# STM32H7R register map
File version: 1.4
CPU: CM7 r0p1, little endian, MPU, FPU, 4 interrupt priority bits
Registers are 32-bit, read-write, reset 0x0 unless marked. A register's access mark holds for its fields unless they carry their own. Offsets are from the block's base; [hi:lo] are bit positions; {n}, {i} and the like mark numbered series; 'fields as' and 'values as' point back to an identical list; <NAME> marks a mode.

## ETH (part 3 of 4) — Ethernet register block
Base 0x40028000
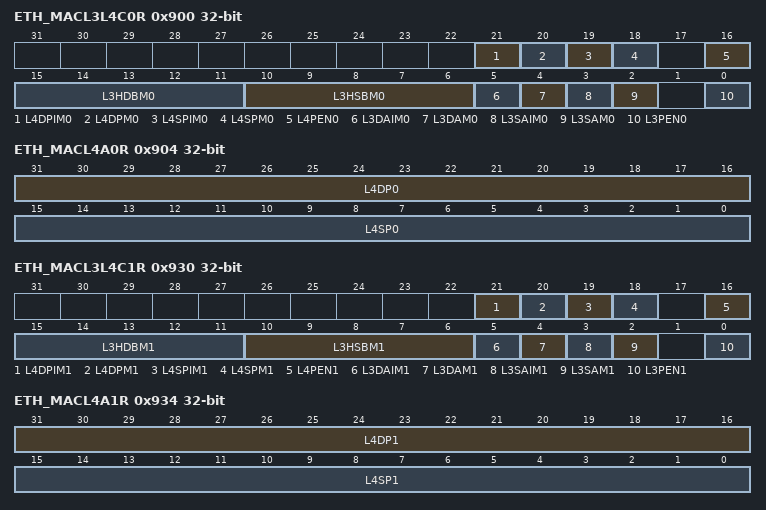
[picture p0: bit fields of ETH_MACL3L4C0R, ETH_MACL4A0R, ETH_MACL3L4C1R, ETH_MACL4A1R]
0x900 ETH_MACL3L4C0R — L3 and L4 control 0 register
  [21] L4DPIM0 — Layer 4 Destination Port Inverse Match Enable When this bit is set, the Layer 4 Destination Port number field is enabled for inverse matching. When this bit is reset, the Layer 4 Destination Port number field is enabled for perfect matching. This bit is valid and applicable only when the L4DPM0 bit is set high.
  [20] L4DPM0 — Layer 4 Destination Port Match Enable When this bit is set, the Layer 4 Destination Port number field is enabled for matching. When this bit is reset, the MAC ignores the Layer 4 Destination Port number field for matching.
  [19] L4SPIM0 — Layer 4 Source Port Inverse Match Enable When this bit is set, the Layer 4 Source Port number field is enabled for inverse matching. When this bit is reset, the Layer 4 Source Port number field is enabled for perfect matching. This bit is valid and applicable only when the L4SPM0 bit is set high.
  [18] L4SPM0 — Layer 4 Source Port Match Enable When this bit is set, the Layer 4 Source Port number field is enabled for matching. When this bit is reset, the MAC ignores the Layer 4 Source Port number field for matching.
  [16] L4PEN0 — Layer 4 Protocol Enable When this bit is set, the Source and Destination Port number fields of UDP packets are used for matching. When this bit is reset, the Source and Destination Port number fields of TCP packets are used for matching. The Layer 4 matching is done only when the L4SPM0 or L4DPM0 bit is set.
  [15:11] L3HDBM0 — Layer 3 IP DA higher bits match This field contains the number of higher bits of IP Destination Address that are masked in the IPv4 packets: .. Bits[12:11] of this field correspond to Bits[6:5] of L3HSBM0 which indicate the number of lower bits of IP Source or Destination Address that are masked in the IPv6 packets. Number of bits masked is given by concatenated values of the L3HDBM0[1:0] and L3HSBM0 bits: .. This field is valid and applicable only when the L3DAM0 or L3SAM0 bit is set.
    0=B_0x0_IPV4_PACKETS (No bits are masked.); 1=B_0x1_IPV4_PACKETS (LSb[0] is masked)
  [10:6] L3HSBM0 — Layer 3 IP SA higher bits match This field contains the number of lower bits of IP source address that are masked for matching in the IPv4 packets. The following list describes the values of this field: .. Condition: IPv6 packets: This field contains Bits[4:0] of L3HSBM0. These bits indicate the number of higher bits of IP source or destination address matched in the IPv6 packets. This field is valid and applicable only when the L3DAM0 or L3SAM0 bit is set high.
    values as L3HDBM0
  [5] L3DAIM0 — Layer 3 IP DA Inverse Match Enable When this bit is set, the Layer 3 IP Destination Address field is enabled for inverse matching. When this bit is reset, the Layer 3 IP Destination Address field is enabled for perfect matching. This bit is valid and applicable only when the L3DAM0 bit is set high.
  [4] L3DAM0 — Layer 3 IP DA Match Enable When this bit is set, the Layer 3 IP Destination Address field is enabled for matching. When this bit is reset, the MAC ignores the Layer 3 IP Destination Address field for matching. Note: When the L3PEN0 bit is set, you should set either this bit or the L3SAM0 bit because either IPv6 DA or SA can be checked for filtering.
  [3] L3SAIM0 — Layer 3 IP SA Inverse Match Enable When this bit is set, the Layer 3 IP Source Address field is enabled for inverse matching. When this bit reset, the Layer 3 IP Source Address field is enabled for perfect matching. This bit is valid and applicable only when the L3SAM0 bit is set.
  [2] L3SAM0 — Layer 3 IP SA Match Enable When this bit is set, the Layer 3 IP Source Address field is enabled for matching. When this bit is reset, the MAC ignores the Layer 3 IP Source Address field for matching. Note: When the L3PEN0 bit is set, you should set either this bit or the L3DAM0 bit because either IPv6 SA or DA can be checked for filtering.
  [0] L3PEN0 — Layer 3 Protocol Enable When this bit is set, the Layer 3 IP Source or Destination Address matching is enabled for IPv6 packets. When this bit is reset, the Layer 3 IP Source or Destination Address matching is enabled for IPv4 packets. The Layer 3 matching is done only when the L3SAM0 or L3DAM0 bit is set.
0x904 ETH_MACL4A0R — Layer4 Address filter 0 register
  [31:16] L4DP0 — Layer 4 Destination Port Number Field When the L4PEN0 bit is reset and the L4DPM0 bit is set in the L3 and L4 control 0 register (ETH_MACL3L4C0R), this field contains the value to be matched with the TCP Destination Port Number field in the IPv4 or IPv6 packets. When the L4PEN0 and L4DPM0 bits are set in L3 and L4 control 0 register (ETH_MACL3L4C0R), this field contains the value to be matched with the UDP Destination Port Number field in the IPv4 or IPv6 packets.
  [15:0] L4SP0 — Layer 4 Source Port Number Field When the L4PEN0 bit is reset and the L4DPM0 bit is set in the L3 and L4 control 0 register (ETH_MACL3L4C0R), this field contains the value to be matched with the TCP Source Port Number field in the IPv4 or IPv6 packets. When the L4PEN0 and L4DPM0 bits are set in L3 and L4 control 0 register (ETH_MACL3L4C0R), this field contains the value to be matched with the UDP Source Port Number field in the IPv4 or IPv6 packets.
0x910 ETH_MACL3A00R — Layer3 Address 0 filter 0 register
  [31:0] L3A00 — Layer 3 Address 0 Field When the L3PEN0 and L3SAM0 bits are set in the L3 and L4 control 0 register (ETH_MACL3L4C0R), this field contains the value to be matched with Bits[31:0] of the IP Source Address field in the IPv6 packets. When the L3PEN0 and L3DAM0 bits are set in the L3 and L4 control 0 register (ETH_MACL3L4C0R), this field contains the value to be matched with Bits[31:0] of the IP Destination Address field in the IPv6 packets. When the L3PEN0 bit is reset and the L3SAM0 bit is set in the L3 and L4 control 0 register (ETH_MACL3L4C0R), this field contains the value to be matched with the IP Source Address field in the IPv4 packets.
0x914 ETH_MACL3A10R — Layer3 Address 1 filter 0 register
  [31:0] L3A10 — Layer 3 Address 1 Field When the L3PEN0 and L3SAM0 bits are set in the L3 and L4 control 0 register (ETH_MACL3L4C0R), this field contains the value to be matched with Bits[63:32] of the IP Source Address field in the IPv6 packets. When the L3PEN0 and L3DAM0 bits are set in the L3 and L4 control 0 register (ETH_MACL3L4C0R), this field contains the value to be matched with Bits[63:32] of the IP Destination Address field in the IPv6 packets. When the L3PEN0 bit is reset and the L3SAM0 bit is set in the L3 and L4 control 0 register (ETH_MACL3L4C0R), this field contains the value to be matched with the IP Destination Address field in the IPv4 packets.
0x918 ETH_MACL3A20R — Layer3 Address 2 filter 0 register
  [31:0] L3A20 — Layer 3 Address 2 Field When the L3PEN0 and L3SAM0 bits are set in the L3 and L4 control 0 register (ETH_MACL3L4C0R), this field contains the value to be matched with Bits[95:64] of the IP Source Address field in the IPv6 packets. When the L3PEN0 and L3DAM0 bits are set in the L3 and L4 control 0 register (ETH_MACL3L4C0R), this field contains the value to be matched with Bits[95:64] of the IP Destination Address field in the IPv6 packets. When the L3PEN0 bit is reset in the L3 and L4 control 0 register (ETH_MACL3L4C0R), this field is not used.
0x91C ETH_MACL3A30R — Layer3 Address 3 filter 0 register
  [31:0] L3A30 — Layer 3 Address 3 Field When the L3PEN0 and L3SAM0 bits are set in the L3 and L4 control 0 register (ETH_MACL3L4C0R), this field contains the value to be matched with Bits[127:96] of the IP Source Address field in the IPv6 packets. When the L3PEN0 and L3DAM0 bits are set in the L3 and L4 control 0 register (ETH_MACL3L4C0R), this field contains the value to be matched with Bits[127:96] of the IP Destination Address field in the IPv6 packets. When the L3PEN0 bit is reset in the L3 and L4 control 0 register (ETH_MACL3L4C0R), this field is not used.
0x930 ETH_MACL3L4C1R — L3 and L4 control 1 register
  [21] L4DPIM1 — Layer 4 Destination Port Inverse Match Enable When this bit is set, the Layer 4 Destination Port number field is enabled for inverse matching. When this bit is reset, the Layer 4 Destination Port number field is enabled for perfect matching. This bit is valid and applicable only when the L4DPM1 bit is set high.
  [20] L4DPM1 — Layer 4 Destination Port Match Enable When this bit is set, the Layer 4 Destination Port number field is enabled for matching. When this bit is reset, the MAC ignores the Layer 4 Destination Port number field for matching.
  [19] L4SPIM1 — Layer 4 Source Port Inverse Match Enable When this bit is set, the Layer 4 Source Port number field is enabled for inverse matching. When this bit is reset, the Layer 4 Source Port number field is enabled for perfect matching. This bit is valid and applicable only when the L4SPM1 bit is set high.
  [18] L4SPM1 — Layer 4 Source Port Match Enable When this bit is set, the Layer 4 Source Port number field is enabled for matching. When this bit is reset, the MAC ignores the Layer 4 Source Port number field for matching.
  [16] L4PEN1 — Layer 4 Protocol Enable When this bit is set, the Source and Destination Port number fields of UDP packets are used for matching. When this bit is reset, the Source and Destination Port number fields of TCP packets are used for matching. The Layer 4 matching is done only when the L4SPM1 or L4DPM1 bit is set.
  [15:11] L3HDBM1 — Layer 3 IP DA higher bits match This field contains the number of lower bits of IP Destination Address that are masked for matching in the IPv4 packets. The following list describes the values of this field: .. Bits[12:11] of this field correspond to Bits[6:5] of L3HSBM1, which indicate the number of lower bits of IP Source or Destination Address that are masked in the IPv6 packets. The following list describes the concatenated values of the L3HDBM1[1:0] and L3HSBM1 bits: .. This field is valid and applicable only when the L3DAM1 or L3SAM1 bit is set.
    values as ETH_MACL3L4C0R.L3HDBM0
  [10:6] L3HSBM1 — Layer 3 IP SA Higher Bits Match This field contains the number of lower bits of IP Source Address that are masked for matching in the IPv4 packets. The following list describes the values of this field: .. This field contains Bits[4:0] of L3HSBM1. These bits indicate the number of higher bits of IP Source or Destination Address matched in the IPv6 packets. This field is valid and applicable only when the L3DAM1 or L3SAM1 bit is set high.
    values as ETH_MACL3L4C0R.L3HDBM0
  [5] L3DAIM1 — Layer 3 IP DA Inverse Match Enable When this bit is set, the Layer 3 IP Destination Address field is enabled for inverse matching. When this bit is reset, the Layer 3 IP Destination Address field is enabled for perfect matching. This bit is valid and applicable only when the L3DAM1 bit is set high.
  [4] L3DAM1 — Layer 3 IP DA Match Enable When this bit is set, the Layer 3 IP Destination Address field is enabled for matching. When this bit is reset, the MAC ignores the Layer 3 IP Destination Address field for matching. Note: When the L3PEN1 bit is set, you should set either this bit or the L3SAM1 bit because either IPv6 DA or SA can be checked for filtering.
  [3] L3SAIM1 — Layer 3 IP SA Inverse Match Enable When this bit is set, the Layer 3 IP Source Address field is enabled for inverse matching. When this bit reset, the Layer 3 IP Source Address field is enabled for perfect matching. This bit is valid and applicable only when the L3SAM1 bit is set.
  [2] L3SAM1 — Layer 3 IP SA Match Enable When this bit is set, the Layer 3 IP Source Address field is enabled for matching. When this bit is reset, the MAC ignores the Layer 3 IP Source Address field for matching. Note: When the L3PEN01 bit is set, you should set either this bit or the L3DAM1 bit because either IPv6 SA or DA can be checked for filtering.
  [0] L3PEN1 — Layer 3 Protocol Enable When this bit is set, the Layer 3 IP Source or Destination Address matching is enabled for IPv6 packets. When this bit is reset, the Layer 3 IP Source or Destination Address matching is enabled for IPv4 packets. The Layer 3 matching is done only when the L3SAM1 or L3DAM1 bit is set.
0x934 ETH_MACL4A1R — Layer 4 address filter 1 register
  [31:16] L4DP1 — Layer 4 Destination Port Number Field When the L4PEN1 bit is reset and the L4DPM1 bit is set in the L3 and L4 control 1 register (ETH_MACL3L4C1R), this field contains the value to be matched with the TCP Destination Port Number field in the IPv4 or IPv6 packets. When the L4PEN1 and L4DPM1 bits are set in L3 and L4 control 1 register (ETH_MACL3L4C1R), this field contains the value to be matched with the UDP Destination Port Number field in the IPv4 or IPv6 packets.
  [15:0] L4SP1 — Layer 4 Source Port Number Field When the L4PEN1 bit is reset and the L4DPM1 bit is set in the L3 and L4 control 1 register (ETH_MACL3L4C1R), this field contains the value to be matched with the TCP Source Port Number field in the IPv4 or IPv6 packets. When the L4PEN1 and L4DPM1 bits are set in L3 and L4 control 1 register (ETH_MACL3L4C1R), this field contains the value to be matched with the UDP Source Port Number field in the IPv4 or IPv6 packets.
0x940 ETH_MACL3A01R — Layer3 address 0 filter 1 Register
  [31:0] L3A01 — Layer 3 Address 0 Field When the L3PEN1 and L3SAM1bits are set in the L3 and L4 control 1 register (ETH_MACL3L4C1R), this field contains the value to be matched with Bits[31:0] of the IP Source Address field in the IPv6 packets. When the L3PEN1 and L3DAM1 bits are set in the L3 and L4 control 1 register (ETH_MACL3L4C1R), this field contains the value to be matched with Bits[31:0] of the IP Destination Address field in the IPv6 packets. When the L3PEN1 bit is reset and the L3SAM1 bit is set in the L3 and L4 control 1 register (ETH_MACL3L4C1R), this field contains the value to be matched with the IP Source Address field in the IPv4 packets.
0x944 ETH_MACL3A11R — Layer3 address 1 filter 1 register
  [31:0] L3A11 — Layer 3 Address 1 Field When the L3PEN1 and L3SAM1 bits are set in the L3 and L4 control 1 register (ETH_MACL3L4C1R), this field contains the value to be matched with Bits[63:32] of the IP Source Address field in the IPv6 packets. When the L3PEN1 and L3DAM1 bits are set in the L3 and L4 control 1 register (ETH_MACL3L4C1R), this field contains the value to be matched with Bits[63:32] of the IP Destination Address field in the IPv6 packets. When the L3PEN1 bit is reset and the L3SAM1 bit is set in the L3 and L4 control 1 register (ETH_MACL3L4C1R), this field contains the value to be matched with the IP Destination Address field in the IPv4 packets.
0x948 ETH_MACL3A21R — Layer3 address 2 filter 1 Register
  [31:0] L3A21 — Layer 3 Address 2 Field When the L3PEN1 and L3SAM1 bits are set in the L3 and L4 control 1 register (ETH_MACL3L4C1R), this field contains the value to be matched with Bits[95:64] of the IP Source Address field in the IPv6 packets. When the L3PEN1 and L3DAM1 bits are set in the L3 and L4 control 1 register (ETH_MACL3L4C1R), this field contains the value to be matched with Bits[95:64] of the IP Destination Address field in the IPv6 packets. When the L3PEN1 bit is reset in the L3 and L4 control 1 register (ETH_MACL3L4C1R), this field is not used.
0x94C ETH_MACL3A31R — Layer3 address 3 filter 1 register
  [31:0] L3A31 — Layer 3 Address 3 Field When the L3PEN1 and L3SAM1 bits are set in the L3 and L4 control 1 register (ETH_MACL3L4C1R), this field contains the value to be matched with Bits[127:96] of the IP Source Address field in the IPv6 packets. When the L3PEN1 and L3DAM1 bits are set in the L3 and L4 control 1 register (ETH_MACL3L4C1R), this field contains the value to be matched with Bits[127:96] of the IP Destination Address field in the IPv6 packets. When the L3PEN1 bit is reset in the L3 and L4 control 1 register (ETH_MACL3L4C1R), this field is not used.
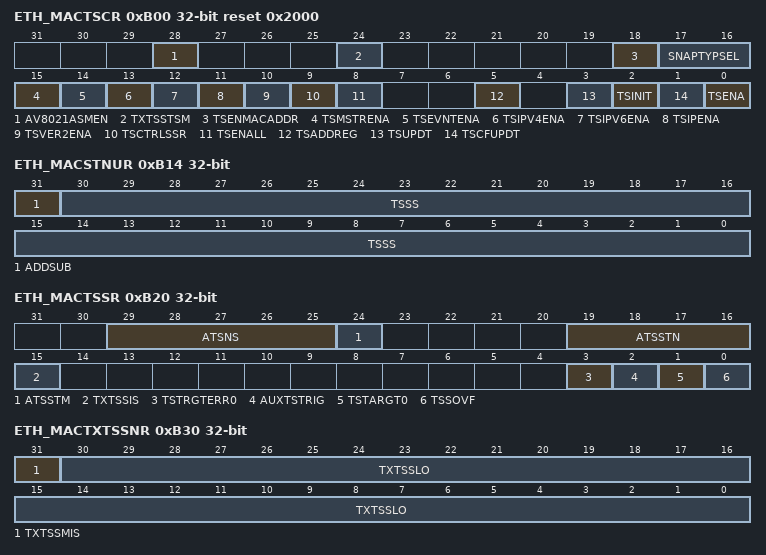
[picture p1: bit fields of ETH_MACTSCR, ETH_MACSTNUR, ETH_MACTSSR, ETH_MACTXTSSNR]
0xB00 ETH_MACTSCR reset 0x2000 — Timestamp control Register
  [28] AV8021ASMEN — AV 802.1AS Mode Enable When this bit is set, the MAC processes only untagged PTP over Ethernet packets for providing PTP status and capturing timestamp snapshots, that is, IEEE 802.1AS operating mode. When PTP offload feature is enabled, for the purpose of PTP offload, the transport specific field in the PTP header is generated and checked based on the value of this bit.
  [24] TXTSSTSM — Transmit Timestamp Status Mode When this bit is set, the MAC overwrites the earlier transmit timestamp status even if it is not read by the software. The MAC indicates this by setting the TXTSSMIS bit of the Tx timestamp status nanoseconds register (ETH_MACTXTSSNR) register. When this bit is reset, the MAC ignores the timestamp status of current packet if the timestamp status of previous packet is not read by the software. The MAC indicates this by setting the TXTSSMIS bit of the Tx timestamp status nanoseconds register (ETH_MACTXTSSNR).
  [18] TSENMACADDR — Enable MAC Address for PTP Packet Filtering When this bit is set, the DA MAC address (that matches any MAC Address register) is used to filter the PTP packets when PTP is directly sent over Ethernet. When this bit is set, received PTP packets with DA containing a special multicast or unicast address that matches the one programmed in MAC address registers are considered for processing as indicated below, when PTP is directly sent over Ethernet. For normal timestamping operation, MAC address registers 0 to 31 is considered for unicast destination address matching. For PTP offload, only MAC address register 0 is considered for unicast destination address matching.
  [17:16] SNAPTYPSEL — Select PTP packets for Taking Snapshots These bits, along with Bits 15 and 14, define the set of PTP packet types for which snapshot needs to be taken. The encoding is given in Table 518: Timestamp Snapshot Dependency on ETH_MACTSCR Bits.
  [15] TSMSTRENA — Enable Snapshot for Messages Relevant to Master When this bit is set, the snapshot is taken only for the messages that are relevant to the master node. Otherwise, the snapshot is taken for the messages relevant to the slave node.
  [14] TSEVNTENA — Enable Timestamp Snapshot for Event Messages When this bit is set, the timestamp snapshot is taken only for event messages (SYNC, Delay_Req, Pdelay_Req, or Pdelay_Resp). When this bit is reset, the snapshot is taken for all messages except Announce, Management, and Signaling. For more information about the timestamp snapshots, see Table 518: Timestamp Snapshot Dependency on ETH_MACTSCR Bits.
  [13] TSIPV4ENA — Enable Processing of PTP Packets Sent over IPv4-UDP When this bit is set, the MAC receiver processes the PTP packets encapsulated in IPv4-UDP packets. When this bit is reset, the MAC ignores the PTP transported over IPv4-UDP packets. This bit is set by default.
  [12] TSIPV6ENA — Enable Processing of PTP Packets Sent over IPv6-UDP When this bit is set, the MAC receiver processes the PTP packets encapsulated in IPv6-UDP packets. When this bit is clear, the MAC ignores the PTP transported over IPv6-UDP packets.
  [11] TSIPENA — Enable Processing of PTP over Ethernet Packets When this bit is set, the MAC receiver processes the PTP packets encapsulated directly in the Ethernet packets. When this bit is reset, the MAC ignores the PTP over Ethernet packets.
  [10] TSVER2ENA — Enable PTP Packet Processing for Version 2 Format When this bit is set, the IEEE 1588 version 2 format is used to process the PTP packets. When this bit is reset, the IEEE 1588 version 1 format is used to process the PTP packets. The IEEE 1588 formats are described in 'PTP Processing and Control'.
  [9] TSCTRLSSR — Timestamp Digital or Binary Rollover Control When this bit is set, the Timestamp Low register rolls over after 0x3B9A_C9FF value (that is, 1 nanosecond accuracy) and increments the timestamp (High) seconds. When this bit is reset, the rollover value of subsecond register is 0x7FFF_FFFF. The subsecond increment must be programmed correctly depending on the PTP reference clock frequency and the value of this bit.
  [8] TSENALL — Enable Timestamp for All Packets When this bit is set, the timestamp snapshot is enabled for all packets received by the MAC.
  [5] TSADDREG — Update Addend Register When this bit is set, the content of the Timestamp Addend register is updated in the PTP block for fine correction. This bit is cleared when the update is complete. This bit should be zero before it is set.
  [3] TSUPDT — Update Timestamp When this bit is set, the system time is updated (added or subtracted) with the value specified in System time seconds update register (ETH_MACSTSUR) and System time nanoseconds update register (ETH_MACSTNUR). This bit should be zero before updating it. This bit is reset when the update is complete in hardware.
  [2] TSINIT — Initialize Timestamp When this bit is set, the system time is initialized (overwritten) with the value specified in the System time seconds update register (ETH_MACSTSUR) and System time nanoseconds update register (ETH_MACSTNUR). This bit should be zero before it is updated. This bit is reset when the initialization is complete.
  [1] TSCFUPDT — Fine or Coarse Timestamp Update When this bit is set, the Fine method is used to update system timestamp. When this bit is reset, Coarse method is used to update the system timestamp.
  [0] TSENA — Enable Timestamp When this bit is set, the timestamp is added for Transmit and Receive packets. When disabled, timestamp is not added for transmit and receive packets and the Timestamp Generator is also suspended. You need to initialize the Timestamp (system time) after enabling this mode. On the Receive side, the MAC processes the 1588 packets only if this bit is set.
0xB04 ETH_MACSSIR — Subsecond increment register
  [23:16] SSINC — Subsecond Increment Value The value programmed in this field is accumulated every clock cycle (of clk_ptp_i) with the contents of the subsecond register. For example, when the PTP clock is 50 MHz (period is 20 ns), you should program 20 (0x14) when the System Time Nanoseconds register has an accuracy of 1 ns [TSCTRLSSR bit is set in Timestamp control Register (ETH_MACTSCR)]. When TSCTRLSSR is cleared, the Nanoseconds register has a resolution of ~0.465 ns. In this case, you should program a value of 43 (0x2B) which is derived by 20 ns/0.465.
0xB08 ETH_MACSTSR ro — System time seconds register
  [31:0] TSS — Timestamp Second The value in this field indicates the current value in seconds of the System Time maintained by the MAC.
0xB0C ETH_MACSTNR ro — System time nanoseconds register
  [30:0] TSSS — Timestamp subseconds The value in this field has the subsecond representation of time, with an accuracy of 0.46 ns. When TSCTRLSSR is set in Timestamp control Register (ETH_MACTSCR), each bit represents 1 ns. The maximum value is 0x3B9A_C9FF after which it rolls-over to zero.
0xB10 ETH_MACSTSUR — System time seconds update register
  [31:0] TSS — Timestamp Seconds The value in this field is the seconds part of the update. When ADDSUB is reset, this field must be programmed with the seconds part of the update value. When ADDSUB is set, this field must be programmed with the complement of the seconds part of the update value. For example, to subtract 2.000000001 seconds from the system time, the TSS field in the ETH_MACSTSUR register must be 0xFFFF_FFFE (that is, 2^32 2). When the ADDSUB bit is set, TSSS[30:0] field cannot be set to 0 in System time nanoseconds update register (ETH_MACSTNUR). The TSSS bitfield must be programmed to 0x7FFF FFFF (resulting in 0.46 ns) even if 0 ns must be subtracted. For example, to subtract 2.000000000 seconds from the system time, the TSS field in the System time seconds update register (ETH_MACSTSUR) must be 0xFFFF FFFE (that is, 2^32 1) and the System time nanoseconds update register (ETH_MACSTNUR) must be 0xFFFF FFFF (ADDSUB = 1 and TSSS[30:0] field = 0x7FFF_FFFF)
0xB14 ETH_MACSTNUR — System time nanoseconds update register
  [31] ADDSUB — Add or Subtract Time When this bit is set, the time value is subtracted with the contents of the update register. When this bit is reset, the time value is added with the contents of the update register.
  [30:0] TSSS — Timestamp subseconds The value in this field is the subseconds part of the update. ADDSUB is 1: This field must be programmed with the complement of the subseconds part of the update value as described. ADDSUB is 0: This field must be programmed with the subseconds part of the update value, with an accuracy based on the TSCTRLSSR bit of the Timestamp control Register (ETH_MACTSCR). TSCTRLSSR field in the Timestamp control Register (ETH_MACTSCR)is 1: - The programmed value must be 10^9 <subsecond value>. - Each bit represents 1 ns and the programmed value should not exceed 0x3B9A_C9FF. TSCTRLSSR field in the Timestamp control Register (ETH_MACTSCR) is 0: - The programmed value must be 2^31 - <subsecond_value>. - Each bit represents an accuracy of 0.46 ns. For example, to subtract 2.000000001 seconds from the system time, then the TSSS field in the ETH_MACSTNUR register must be 0x7FFF_FFFF (that is, 2^31 1), when TSCTRLSSR bit in Timestamp control Register (ETH_MACTSCR) is reset and 0x3B9A_C9FF (that is, 10^9 1), when TSCTRLSSR bit in Timestamp control Register (ETH_MACTSCR) is set. When the ADDSUB bit is set, TSSS[30:0] field cannot be set to 0. The TSSS bitfield must be programmed to 0x7FFF FFFF (resulting in 0.46 ns) even if 0 ns must be subtracted. For example, to subtract 2.000000000 seconds from the system time, System time nanoseconds update register (ETH_MACSTNUR) must be 0xFFFF FFFF (ADDSUB = 1 and TSSS[30:0] = 0) and the TSS field in the System time seconds update register (ETH_MACSTSUR) must be 0xFFFF FFFE (that is, 2^32 1).
0xB18 ETH_MACTSAR — Timestamp addend register
  [31:0] TSAR — Timestamp Addend Register This field indicates the 32-bit time value to be added to the Accumulator register to achieve time synchronization.
0xB20 ETH_MACTSSR access per field — Timestamp status register
  [29:25] ATSNS ro — Number of Auxiliary Timestamp Snapshots This field indicates the number of Snapshots available in the FIFO. A value equal to the depth of FIFO (4) indicates that the Auxiliary Snapshot FIFO is full. These bits are cleared (to 00000) when the Auxiliary snapshot FIFO clear bit is set.
  [24] ATSSTM rw read-clears — Auxiliary Timestamp Snapshot Trigger Missed This bit is set when the Auxiliary timestamp snapshot FIFO is full and external trigger was set. This indicates that the latest snapshot is not stored in the FIFO.
  [19:16] ATSSTN rw read-clears — Auxiliary Timestamp Snapshot Trigger Identifier These bits identify the Auxiliary trigger inputs for which the timestamp available in the Auxiliary Snapshot Register is applicable. When more than one bit is set at the same time, it means that corresponding auxiliary triggers were sampled at the same clock. These bits are applicable only if the number of Auxiliary snapshots is more than one. One bit is assigned for each trigger as shown in the following list: Bit 16: Auxiliary trigger 0 Bit 17: Auxiliary trigger 1 Bit 18: Auxiliary trigger 2 Bit 19: Auxiliary trigger 3 The software can read this register to find the triggers that are set when the timestamp is taken.
  [15] TXTSSIS rw read-clears — Tx Timestamp Status Interrupt Status When drop transmit status is enabled in MTL, this bit is set when the captured transmit timestamp is updated in the Tx timestamp status nanoseconds register (ETH_MACTXTSSNR) and Tx timestamp status seconds register (ETH_MACTXTSSSR). When PTP offload feature is enabled, this bit is set when the captured transmit timestamp is updated in the Tx timestamp status nanoseconds register (ETH_MACTXTSSNR) and Tx timestamp status seconds register (ETH_MACTXTSSSR), for PTO generated Delay Request and Pdelay request packets. This bit is cleared when the Tx timestamp status seconds register (ETH_MACTXTSSSR) is read (or write of 1 when RCWE bit in CSR software control register (ETH_MACCSRSWCR) is set).
  [3] TSTRGTERR0 rw read-clears — Timestamp Target Time Error This bit is set when the latest target time programmed in the PPS target time seconds register (ETH_MACPPSTTSR) and PPS target time nanoseconds register (ETH_MACPPSTTNR) elapses. This bit is cleared when the application reads this bit (or write of 1 when RCWE bit in CSR software control register (ETH_MACCSRSWCR) is set).
  [2] AUXTSTRIG rw read-clears — Auxiliary Timestamp Trigger Snapshot This bit is set high when the auxiliary snapshot is written to the FIFO. This bit is cleared when the application reads this bit (or write of 1 when RCWE bit in CSR software control register (ETH_MACCSRSWCR) is set).
  [1] TSTARGT0 rw read-clears — Timestamp Target Time Reached When set, this bit indicates that the value of system time is greater than or equal to the value specified in the PPS target time seconds register (ETH_MACPPSTTSR) and PPS target time nanoseconds register (ETH_MACPPSTTNR). This bit is cleared when the application reads this bit (or write of 1 when RCWE bit in CSR software control register (ETH_MACCSRSWCR) is set)
  [0] TSSOVF rw read-clears — Timestamp Seconds Overflow When this bit is set, it indicates that the seconds value of the timestamp (when supporting version 2 format) has overflowed beyond 32'hFFFF_FFFF. This bit is cleared when the application reads this bit (or write of 1 when RCWE bit in CSR software control register (ETH_MACCSRSWCR) is set)
0xB30 ETH_MACTXTSSNR access per field — Tx timestamp status nanoseconds register
  [31] TXTSSMIS ro — Transmit Timestamp Status Missed When this bit is set, it indicates one of the following: The timestamp of the current packet is ignored if TXTSSTSM bit of the Timestamp control Register (ETH_MACTSCR) is reset The timestamp of the previous packet is overwritten with timestamp of the current packet if TXTSSTSM bit of the Timestamp control Register (ETH_MACTSCR) is set.
  [30:0] TXTSSLO rw read-clears — Transmit Timestamp Status Low This field contains the 31 bits of the Nanoseconds field of the Transmit packet's captured timestamp.
0xB34 ETH_MACTXTSSSR ro — Tx timestamp status seconds register
  [31:0] TXTSSHI — Transmit Timestamp Status High This field contains the lower 32 bits of the Seconds field of Transmit packet's captured timestamp.
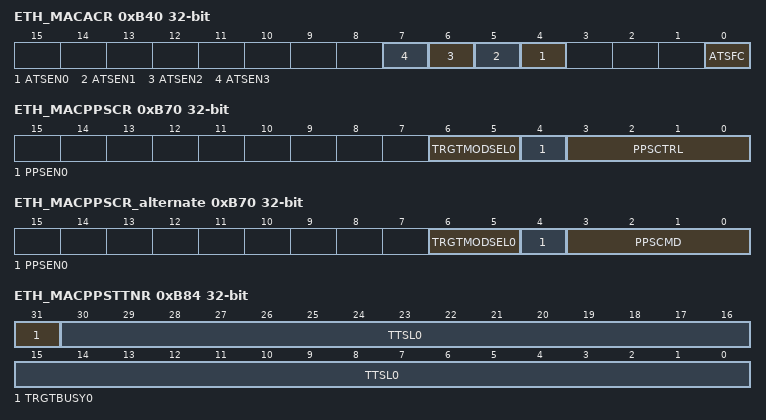
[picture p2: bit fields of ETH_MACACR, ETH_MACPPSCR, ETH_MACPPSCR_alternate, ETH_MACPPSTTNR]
0xB40 ETH_MACACR — Auxiliary control register
  [n+4] ATSEN{n} (n=0..3) — Auxiliary Snapshot {n} Enable This bit controls the capturing of Auxiliary Snapshot Trigger {n}. When this bit is set, the auxiliary snapshot of the event on eth_ptp_trg{n} input is enabled. When this bit is reset, the events on this input are ignored.
  [0] ATSFC — Auxiliary Snapshot FIFO Clear When set, this bit resets the pointers of the Auxiliary Snapshot FIFO. This bit is cleared when the pointers are reset and the FIFO is empty. When this bit is high, the auxiliary snapshots are stored in the FIFO.
0xB48 ETH_MACATSNR ro — Auxiliary timestamp nanoseconds register
  [30:0] AUXTSLO — Auxiliary Timestamp Contains the lower 31 bits (nanoseconds field) of the auxiliary timestamp.
0xB4C ETH_MACATSSR ro — Auxiliary timestamp seconds register
  [31:0] AUXTSHI — Auxiliary Timestamp Contains the lower 32 bits of the Seconds field of the auxiliary timestamp.
0xB50 ETH_MACTSIACR — Timestamp Ingress asymmetric correction register
  [31:0] OSTIAC — One-Step Timestamp Ingress Asymmetry Correction This field contains the ingress path asymmetry value to be added to correctionField of Pdelay_Resp PTP packet. The programmed value should be in units of nanoseconds and multiplied by 2^16. For example, 2.5 ns is represented as 0x00028000. The value can also be negative, which is represented in 2's complement form with bit 31 representing the sign bit.
0xB54 ETH_MACTSEACR — Timestamp Egress asymmetric correction register
  [31:0] OSTEAC — One-Step Timestamp Egress Asymmetry Correction This field contains the egress path asymmetry value to be subtracted from correctionField of Pdelay_Resp PTP packet. The programmed value must be the negated value in units of nanoseconds multiplied by 2^16. For example, if the required correction is +2.5 ns, the programmed value must be 0xFFFD_8000, which is the 2's complement of 0x0002_8000(2.5 * 2^16). Similarly, if the required correction is -3.3 ns, the programmed value is 0x0003_4CCC (3.3 *2^16).
0xB58 ETH_MACTSICNR — Timestamp Ingress correction nanosecond register
  [31:0] TSIC — Timestamp Ingress Correction This field contains the ingress path correction value as defined by the Ingress Correction expression.
0xB5C ETH_MACTSECNR — Timestamp Egress correction nanosecond register
  [31:0] TSEC — Timestamp Egress Correction This field contains the nanoseconds part of the egress path correction value as defined by the Egress Correction expression.
0xB70 ETH_MACPPSCR — PPS control register
  [6:5] TRGTMODSEL0 — Target Time Register Mode for PPS Output This field indicates the Target Time registers (PPS target time seconds register (ETH_MACPPSTTSR) and PPS target time nanoseconds register (ETH_MACPPSTTNR)) mode for PPS output signal:
    0=Target Time registers are programmed only for generating the interrupt event; 1=Reserved, must not be used; 2=Target Time registers are programmed for generating the interrupt event and starting or stopping the PPS output signal generation; 3=Target Time registers are programmed only for starting or stopping the PPS output signal generation. No interrupt is asserted.
  [4] PPSEN0 — Flexible PPS Output Mode Enable When this bit is set, PPSCTRL[3:0] function as PPSCMD[3:0]. When this bit is reset, PPSCTRL[3:0] function as PPSCTRL (Fixed PPS mode).
  [3:0] PPSCTRL — PPS Output Frequency Control This field controls the frequency of the PPS output (eth_ptp_pps_out) signal. The default value of PPSCTRL is 0000, and the PPS output is 1 pulse (of width clk_ptp_i) every second. For other values of PPSCTRL, the PPS output becomes a generated clock of following frequencies: .. Note: In the binary rollover mode, the PPS output (eth_ptp_pps_out) has a duty cycle of 50 percent with these frequencies. In the digital rollover mode, the PPS output frequency is an average number. The actual clock is of different frequency that gets synchronized every second. For example: When PPSCTRL = 0001, the PPS (1 Hz) has a low period of 537 ms and a high period of 463 ms When PPSCTRL = 0010, the PPS (2 Hz) is a sequence of One clock of 50 percent duty cycle and 537 ms period Second clock of 463 ms period (268 ms low and 195 ms high) When PPSCTRL = 0011, the PPS (4 Hz) is a sequence of Three clocks of 50 percent duty cycle and 268 ms period Fourth clock of 195 ms period (134 ms low and 61 ms high) This behavior is because of the non-linear toggling of bits in the digital rollover mode in the ETH_MACSTNR register.
    1=The binary rollover is 2 Hz, and the digital rollover is 1 Hz; 2=The binary rollover is 4 Hz, and the digital rollover is 2 Hz; 3=The binary rollover is 8 Hz, and the digital rollover is 4 Hz; 4=The binary rollover is 16 Hz, and the digital rollover is 8 Hz; 15=The binary rollover is 32.768 KHz and the digital rollover is 16.384 KHz
0xB70 ETH_MACPPSCR_alternate (alternate view of ETH_MACPPSCR) — PPS control register
  [6:5] TRGTMODSEL0 — Target Time Register Mode for PPS Output This field indicates the Target Time registers (MAC registers 96 and 97) mode for PPS output signal:
    values as ETH_MACPPSCR.TRGTMODSEL0
  [4] PPSEN0 — Flexible PPS Output Mode Enable When this bit is set, Bits[3:0] function as PPSCMD[3:0]. When this bit is reset, Bits[3:0] function as PPSCTRL (Fixed PPS mode).
  [3:0] PPSCMD — Flexible PPS Output (eth_ptp_pps_out) Control Programming these bits with a non-zero value instructs the MAC to initiate an event. When the command is transferred or synchronized to the PTP clock domain, these bits get cleared automatically. The software should ensure that these bits are programmed only when they are all zero. The following list describes the values of PPSCMD0: This command generates single pulse rising at the start point defined in Target Time Registers (register 455 and 456) and of a duration defined in the PPS Width Register. This command generates the train of pulses rising at the start point defined in the Target Time Registers and of a duration defined in the PPS Width Register and repeated at interval defined in the PPS Interval Register. By default, the PPS pulse train is free-running unless stopped by the 'Stop Pulse train at time' or 'Stop Pulse Train immediately' commands. This command cancels the START Single Pulse and START Pulse Train commands if the system time has not crossed the programmed start time. This command stops the train of pulses initiated by the START Pulse Train command (PPSCMD[3:0] = 0010) after the time programmed in the Target Time registers elapses. This command immediately stops the train of pulses initiated by the START Pulse Train command (PPSCMD[3:0] = 0010). This command cancels the STOP pulse train at time command if the programmed stop time has not elapsed. The PPS pulse train becomes free-running on the successful execution of this command. 0111 to 1111: Reserved, must not be used
    0=No Command; 1=START Single Pulse; 2=START Pulse Train; 3=Cancel START; 4=STOP Pulse Train at time; 5=STOP Pulse Train immediately; 6=Cancel STOP Pulse train
0xB80 ETH_MACPPSTTSR — PPS target time seconds register
  [31:0] TSTRH0 — PPS Target Time Seconds Register This field stores the time in seconds. When the timestamp value matches or exceeds both Target Timestamp registers, the MAC starts or stops the PPS signal output and generates an interrupt (if enabled) based on Target Time mode selected for the corresponding PPS output in the PPS control register (ETH_MACPPSCR).
0xB84 ETH_MACPPSTTNR — PPS target time nanoseconds register
  [31] TRGTBUSY0 — PPS Target Time Register Busy The MAC sets this bit when the PPSCMD0 field in the PPS control register (ETH_MACPPSCR) is programmed to 010 or 011. Programming the PPSCMD0 field to 010 or 011 instructs the MAC to synchronize the Target Time Registers to the PTP clock domain. The MAC clears this bit after synchronizing the Target Time Registers with the PTP clock domain The application must not update the Target Time Registers when this bit is read as 1. Otherwise, the synchronization of the previous programmed time gets corrupted.
  [30:0] TTSL0 — Target Time Low for PPS Register This register stores the time in (signed) nanoseconds. When the value of the timestamp matches the value in both Target Timestamp registers, the MAC starts or stops the PPS signal output and generates an interrupt (if enabled) based on the TRGTMODSEL0 field (Bits [6:5]) in PPS control register (ETH_MACPPSCR). When the TSCTRLSSR bit is set in the Timestamp control Register (ETH_MACTSCR), this value should not exceed 0x3B9A_C9FF. The actual start or stop time of the PPS signal output may have an error margin up to one unit of subsecond increment value.
0xB88 ETH_MACPPSIR — PPS interval register
  [31:0] PPSINT0 — PPS Output Signal Interval These bits store the interval between the rising edges of PPS signal output. The interval is stored in terms of number of units of subsecond increment value. You need to program one value less than the required interval. For example, if the PTP reference clock is 50 MHz (period of 20 ns), and desired interval between the rising edges of PPS signal output is 100 ns (that is, 5 units of subsecond increment value), you should program value 4 (5-1) in this register.
0xB8C ETH_MACPPSWR — PPS width register
  [31:0] PPSWIDTH0 — PPS Output Signal Width These bits store the width between the rising edge and corresponding falling edge of PPS signal output. The width is stored in terms of number of units of subsecond increment value. You need to program one value less than the required interval. For example, if PTP reference clock is 50 MHz (period of 20 ns), and width between the rising and corresponding falling edges of PPS signal output is 80 ns (that is, four units of subsecond increment value), you should program value 3 (4-1) in this register. Note: The value programmed in this register must be lesser than the value programmed in PPS interval register (ETH_MACPPSIR).
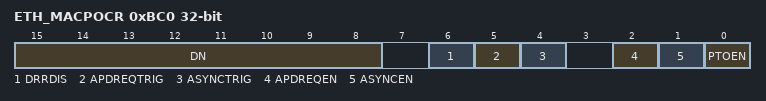
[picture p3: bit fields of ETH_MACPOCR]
0xBC0 ETH_MACPOCR — PTP Offload control register
  [15:8] DN — Domain Number This field indicates the domain Number in which the PTP node is operating.
  [6] DRRDIS — Disable PTO Delay Request/Response response generation When this bit is set, the Delay Request and Delay response are not generated for received SYNC and Delay request packet respectively, as required by the programmed mode.
  [5] APDREQTRIG — Automatic PTP Pdelay_Req message Trigger When this bit is set, one PTP Pdelay_Req message is transmitted. This bit is automatically cleared after the PTP Pdelay_Req message is transmitted. The application should set the APDREQEN bit for this operation.
  [4] ASYNCTRIG — Automatic PTP SYNC message Trigger When this bit is set, one PTP SYNC message is transmitted. This bit is automatically cleared after the PTP SYNC message is transmitted. The application should set the ASYNCEN bit for this operation.
  [2] APDREQEN — Automatic PTP Pdelay_Req message Enable When this bit is set, PTP Pdelay_Req message is generated periodically based on interval programmed or trigger from application, when the MAC is programmed to be in Peer-to-Peer Transparent mode.
  [1] ASYNCEN — Automatic PTP SYNC message Enable When this bit is set, PTP SYNC message is generated periodically based on interval programmed or trigger from application, when the MAC is programmed to be in Clock Master mode.
  [0] PTOEN — PTP Offload Enable When this bit is set, the PTP Offload feature is enabled.

## Notices in the file
Copyright (c) 2026 STMicroelectronics.
SPDX-License-Identifier: Apache-2.0
Licensed under the Apache License, Version 2.0 (the "License");
you may not use this file except in compliance with the License.
You may obtain a copy of the License at
http://www.apache.org/licenses/LICENSE-2.0
Unless required by applicable law or agreed to in writing, software
distributed under the License is distributed on an "AS IS" BASIS,
WITHOUT WARRANTIES OR CONDITIONS OF ANY KIND, either express or implied.
See the License for the specific language governing permissions and
limitations under the License.
